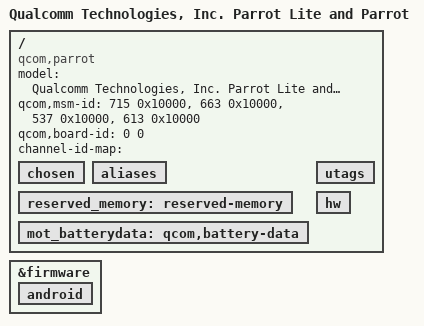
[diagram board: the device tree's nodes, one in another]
/dts-v1/;

#include "parrot.dtsi"

/ {
	model = "Qualcomm Technologies, Inc. Parrot Lite and Parrot";
	compatible = "qcom,parrot";
	qcom,msm-id = <715 0x10000>, <663 0x10000>, <537 0x10000>, <613 0x10000>;
	qcom,board-id = <0 0>;
	channel-id-map = "";
/*
 * Some nodes need labels assigned to appear in __symbols__
 */
	chosen: chosen { };
	aliases: aliases { };
	reserved_memory: reserved-memory { };
	mot_batterydata: qcom,battery-data { };
	utags: utags { };
	hw: hw { };
};

&reserved_memory {
	/delete-node/ qcom_ramoops;
};

&firmware {
	android {
		/delete-node/ fstab;
	};
};

/delete-node/ &mem_offline;
